# platform_designer_hps_system_hps_0_hps register map
Vendor: default_vendor.com; File version: 0.0
Registers are 32-bit, read-write, reset 0x0 unless marked. A register's access mark holds for its fields unless they carry their own. Offsets are from the block's base; [hi:lo] are bit positions; {n}, {i} and the like mark numbered series.

## sysmgr (part 2 of 3) — Registers in the System Manager module
Base 0xFFD08000
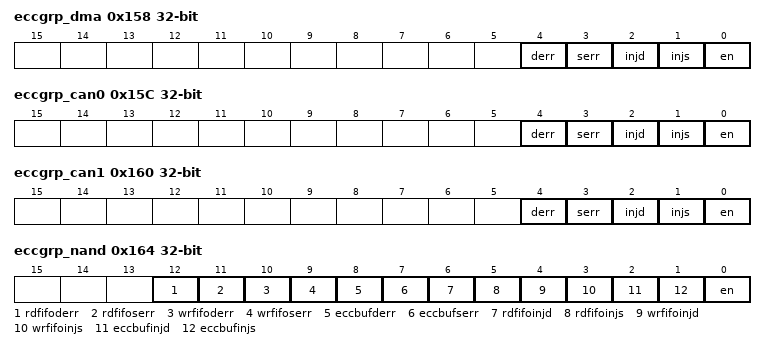
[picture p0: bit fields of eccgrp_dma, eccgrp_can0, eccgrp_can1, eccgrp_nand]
0x158 eccgrp_dma — This register is used to enable ECC on the DMA RAM. ECC errors can be injected into the write path using bits in this register. This register contains interrupt status of the ECC single/double bit error. Only reset by a cold reset (ignores warm reset).
  [4] derr write-1-clears — This bit is an interrupt status bit for DMA RAM ECC double bit, non-correctable error. It is set by hardware when double bit, non-correctable error occurs in DMA RAM. Software needs to write 1 into this bit to clear the interrupt status.
  [3] serr write-1-clears — This bit is an interrupt status bit for DMA RAM ECC single, correctable error. It is set by hardware when single, correctable error occurs in DMA RAM. Software needs to write 1 into this bit to clear the interrupt status.
  [2] injd — Changing this bit from zero to one injects a double, non-correctable error into the DMA RAM. This only injects one double bit error into the DMA RAM.
  [1] injs — Changing this bit from zero to one injects a single, correctable error into the DMA RAM. This only injects one error into the DMA RAM.
  [0] en — Enable ECC for DMA RAM
0x15C eccgrp_can0 — This register is used to enable ECC on the CAN0 RAM. ECC errors can be injected into the write path using bits in this register. This register contains interrupt status of the ECC single/double bit error. Only reset by a cold reset (ignores warm reset).
  [4] derr write-1-clears — This bit is an interrupt status bit for CAN0 RAM ECC double bit, non-correctable error. It is set by hardware when double bit, non-correctable error occurs in CAN0 RAM. Software needs to write 1 into this bit to clear the interrupt status.
  [3] serr write-1-clears — This bit is an interrupt status bit for CAN0 RAM ECC single, correctable error. It is set by hardware when single, correctable error occurs in CAN0 RAM. Software needs to write 1 into this bit to clear the interrupt status.
  [2] injd — Changing this bit from zero to one injects a double, non-correctable error into the CAN0 RAM. This only injects one double bit error into the CAN0 RAM.
  [1] injs — Changing this bit from zero to one injects a single, correctable error into the CAN0 RAM. This only injects one error into the CAN0 RAM.
  [0] en — Enable ECC for CAN0 RAM
0x160 eccgrp_can1 — This register is used to enable ECC on the CAN1 RAM. ECC errors can be injected into the write path using bits in this register. This register contains interrupt status of the ECC single/double bit error. Only reset by a cold reset (ignores warm reset).
  [4] derr write-1-clears — This bit is an interrupt status bit for CAN1 RAM ECC double bit, non-correctable error. It is set by hardware when double bit, non-correctable error occurs in CAN1 RAM. Software needs to write 1 into this bit to clear the interrupt status.
  [3] serr write-1-clears — This bit is an interrupt status bit for CAN1 RAM ECC single, correctable error. It is set by hardware when single, correctable error occurs in CAN1 RAM. Software needs to write 1 into this bit to clear the interrupt status.
  [2] injd — Changing this bit from zero to one injects a double, non-correctable error into the CAN1 RAM. This only injects one double bit error into the CAN1 RAM.
  [1] injs — Changing this bit from zero to one injects a single, correctable error into the CAN1 RAM. This only injects one error into the CAN1 RAM.
  [0] en — Enable ECC for CAN1 RAM
0x164 eccgrp_nand — This register is used to enable ECC on the NAND RAM. ECC errors can be injected into the write path using bits in this register. This register contains interrupt status of the ECC single/double bit error. Only reset by a cold reset (ignores warm reset).
  [12] rdfifoderr write-1-clears — This bit is an interrupt status bit for NAND RDFIFO RAM ECC double bit, non-correctable error. It is set by hardware when double bit, non-correctable error occurs in NAND RDFIFO RAM. Software needs to write 1 into this bit to clear the interrupt status.
  [11] rdfifoserr write-1-clears — This bit is an interrupt status bit for NAND RDFIFO RAM ECC single, correctable error. It is set by hardware when single, correctable error occurs in NAND RDFIFO RAM. Software needs to write 1 into this bit to clear the interrupt status.
  [10] wrfifoderr write-1-clears — This bit is an interrupt status bit for NAND WRFIFO RAM ECC double bit, non-correctable error. It is set by hardware when double bit, non-correctable error occurs in NAND WRFIFO RAM. Software needs to write 1 into this bit to clear the interrupt status.
  [9] wrfifoserr write-1-clears — This bit is an interrupt status bit for NAND WRFIFO RAM ECC single, correctable error. It is set by hardware when single, correctable error occurs in NAND WRFIFO RAM. Software needs to write 1 into this bit to clear the interrupt status.
  [8] eccbufderr write-1-clears — This bit is an interrupt status bit for NAND ECCBUFFER RAM ECC double bit, non-correctable error. It is set by hardware when double bit, non-correctable error occurs in NAND ECCBUFFER RAM. Software needs to write 1 into this bit to clear the interrupt status.
  [7] eccbufserr write-1-clears — This bit is an interrupt status bit for NAND ECCBUFFER RAM ECC single, correctable error. It is set by hardware when single, correctable error occurs in NAND ECCBUFFER RAM. Software needs to write 1 into this bit to clear the interrupt status.
  [6] rdfifoinjd — Changing this bit from zero to one injects a double, non-correctable error into the NAND RDFIFO RAM. This only injects one double bit error into the NAND RDFIFO RAM.
  [5] rdfifoinjs — Changing this bit from zero to one injects a single, correctable error into the NAND RDFIFO RAM. This only injects one error into the NAND RDFIFO RAM.
  [4] wrfifoinjd — Changing this bit from zero to one injects a double, non-correctable error into the NAND WRFIFO RAM. This only injects one double bit error into the NAND WRFIFO RAM.
  [3] wrfifoinjs — Changing this bit from zero to one injects a single, correctable error into the NAND WRFIFO RAM. This only injects one error into the NAND WRFIFO RAM.
  [2] eccbufinjd — Changing this bit from zero to one injects a double, non-correctable error into the NAND ECCBUFFER RAM. This only injects one double bit error into the NAND ECCBUFFER RAM.
  [1] eccbufinjs — Changing this bit from zero to one injects a single, correctable error into the NAND ECCBUFFER RAM. This only injects one error into the NAND ECCBUFFER RAM.
  [0] en — Enable ECC for NAND RAM
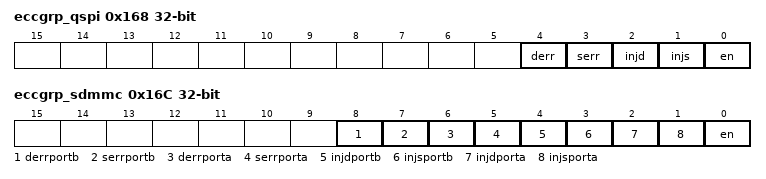
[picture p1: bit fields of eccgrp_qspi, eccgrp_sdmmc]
0x168 eccgrp_qspi — This register is used to enable ECC on the QSPI RAM. ECC errors can be injected into the write path using bits in this register. This register contains interrupt status of the ECC single/double bit error. Only reset by a cold reset (ignores warm reset).
  [4] derr write-1-clears — This bit is an interrupt status bit for QSPI RAM ECC double bit, non-correctable error. It is set by hardware when double bit, non-correctable error occurs in QSPI RAM. Software needs to write 1 into this bit to clear the interrupt status.
  [3] serr write-1-clears — This bit is an interrupt status bit for QSPI RAM ECC single, correctable error. It is set by hardware when single, correctable error occurs in QSPI RAM. Software needs to write 1 into this bit to clear the interrupt status.
  [2] injd — Changing this bit from zero to one injects a double, non-correctable error into the QSPI RAM. This only injects one double bit error into the QSPI RAM.
  [1] injs — Changing this bit from zero to one injects a single, correctable error into the QSPI RAM. This only injects one error into the QSPI RAM.
  [0] en — Enable ECC for QSPI RAM
0x16C eccgrp_sdmmc — This register is used to enable ECC on the SDMMC RAM.ECC errors can be injected into the write path using bits in this register. Only reset by a cold reset (ignores warm reset).
  [8] derrportb write-1-clears — This bit is an interrupt status bit for SDMMC Port B RAM ECC double bit, non-correctable error. It is set by hardware when double bit, non-correctable error occurs in SDMMC Port B RAM. Software needs to write 1 into this bit to clear the interrupt status.
  [7] serrportb write-1-clears — This bit is an interrupt status bit for SDMMC Port B RAM ECC single, correctable error. It is set by hardware when single, correctable error occurs in SDMMC Port B RAM. Software needs to write 1 into this bit to clear the interrupt status.
  [6] derrporta write-1-clears — This bit is an interrupt status bit for SDMMC Port A RAM ECC double bit, non-correctable error. It is set by hardware when double bit, non-correctable error occurs in SDMMC Port A RAM. Software needs to write 1 into this bit to clear the interrupt status.
  [5] serrporta write-1-clears — This bit is an interrupt status bit for SDMMC Port A RAM ECC single, correctable error. It is set by hardware when single, correctable error occurs in SDMMC Port A RAM. Software needs to write 1 into this bit to clear the interrupt status.
  [4] injdportb — Changing this bit from zero to one injects a double, non-correctable error into the SDMMC RAM at Port B. This only injects one double bit error into the SDMMC RAM at Port B.
  [3] injsportb — Changing this bit from zero to one injects a single, correctable error into the SDMMC RAM at Port B. This only injects one error into the SDMMC RAM at Port B.
  [2] injdporta — Changing this bit from zero to one injects a double, non-correctable error into the SDMMC RAM at Port A. This only injects one double bit error into the SDMMC RAM at Port A.
  [1] injsporta — Changing this bit from zero to one injects a single, correctable error into the SDMMC RAM at Port A. This only injects one error into the SDMMC RAM at Port A.
  [0] en — Enable ECC for SDMMC RAM
0x400 pinmuxgrp_EMACIO0 — This register is used to control the peripherals connected to emac0_tx_clk Only reset by a cold reset (ignores warm reset). NOTE: These registers should not be modified after IO configuration.There is no support for dynamically changing the Pin Mux selections.
  [1:0] sel — Select peripheral signals connected emac0_tx_clk. 0 : Pin is connected to GPIO/LoanIO number 0. 1 : Pin is connected to Peripheral signal not applicable. 2 : Pin is connected to Peripheral signal not applicable. 3 : Pin is connected to Peripheral signal RGMII0.TX_CLK.
{0x400+4i} pinmuxgrp_EMACIO{i} (i=1..4) — This register is used to control the peripherals connected to emac0_tx_d{i-1} Only reset by a cold reset (ignores warm reset). NOTE: These registers should not be modified after IO configuration.There is no support for dynamically changing the Pin Mux selections.
  [1:0] sel — Select peripheral signals connected emac0_tx_d{i-1}. 0 : Pin is connected to GPIO/LoanIO number {i}. 1 : Pin is connected to Peripheral signal not applicable. 2 : Pin is connected to Peripheral signal USB1.D{i-1}. 3 : Pin is connected to Peripheral signal RGMII0.TXD{i-1}.
0x414 pinmuxgrp_EMACIO5 — This register is used to control the peripherals connected to emac0_rx_d0 Only reset by a cold reset (ignores warm reset). NOTE: These registers should not be modified after IO configuration.There is no support for dynamically changing the Pin Mux selections.
  [1:0] sel — Select peripheral signals connected emac0_rx_d0. 0 : Pin is connected to GPIO/LoanIO number 5. 1 : Pin is connected to Peripheral signal not applicable. 2 : Pin is connected to Peripheral signal USB1.D4. 3 : Pin is connected to Peripheral signal RGMII0.RXD0.
0x418 pinmuxgrp_EMACIO6 — This register is used to control the peripherals connected to emac0_mdio Only reset by a cold reset (ignores warm reset). NOTE: These registers should not be modified after IO configuration.There is no support for dynamically changing the Pin Mux selections.
  [1:0] sel — Select peripheral signals connected emac0_mdio. 0 : Pin is connected to GPIO/LoanIO number 6. 1 : Pin is connected to Peripheral signal I2C2.SDA. 2 : Pin is connected to Peripheral signal USB1.D5. 3 : Pin is connected to Peripheral signal RGMII0.MDIO.
0x41C pinmuxgrp_EMACIO7 — This register is used to control the peripherals connected to emac0_mdc Only reset by a cold reset (ignores warm reset). NOTE: These registers should not be modified after IO configuration.There is no support for dynamically changing the Pin Mux selections.
  [1:0] sel — Select peripheral signals connected emac0_mdc. 0 : Pin is connected to GPIO/LoanIO number 7. 1 : Pin is connected to Peripheral signal I2C2.SCL. 2 : Pin is connected to Peripheral signal USB1.D6. 3 : Pin is connected to Peripheral signal RGMII0.MDC.
0x420 pinmuxgrp_EMACIO8 — This register is used to control the peripherals connected to emac0_rx_ctl Only reset by a cold reset (ignores warm reset). NOTE: These registers should not be modified after IO configuration.There is no support for dynamically changing the Pin Mux selections.
  [1:0] sel — Select peripheral signals connected emac0_rx_ctl. 0 : Pin is connected to GPIO/LoanIO number 8. 1 : Pin is connected to Peripheral signal not applicable. 2 : Pin is connected to Peripheral signal USB1.D7. 3 : Pin is connected to Peripheral signal RGMII0.RX_CTL.
0x424 pinmuxgrp_EMACIO9 — This register is used to control the peripherals connected to emac0_tx_ctl Only reset by a cold reset (ignores warm reset). NOTE: These registers should not be modified after IO configuration.There is no support for dynamically changing the Pin Mux selections.
  [1:0] sel — Select peripheral signals connected emac0_tx_ctl. 0 : Pin is connected to GPIO/LoanIO number 9. 1 : Pin is connected to Peripheral signal not applicable. 2 : Pin is connected to Peripheral signal not applicable. 3 : Pin is connected to Peripheral signal RGMII0.TX_CTL.
0x428 pinmuxgrp_EMACIO10 — This register is used to control the peripherals connected to emac0_rx_clk Only reset by a cold reset (ignores warm reset). NOTE: These registers should not be modified after IO configuration.There is no support for dynamically changing the Pin Mux selections.
  [1:0] sel — Select peripheral signals connected emac0_rx_clk. 0 : Pin is connected to GPIO/LoanIO number 10. 1 : Pin is connected to Peripheral signal not applicable. 2 : Pin is connected to Peripheral signal USB1.CLK. 3 : Pin is connected to Peripheral signal RGMII0.RX_CLK.
0x42C pinmuxgrp_EMACIO11 — This register is used to control the peripherals connected to emac0_rx_d1 Only reset by a cold reset (ignores warm reset). NOTE: These registers should not be modified after IO configuration.There is no support for dynamically changing the Pin Mux selections.
  [1:0] sel — Select peripheral signals connected emac0_rx_d1. 0 : Pin is connected to GPIO/LoanIO number 11. 1 : Pin is connected to Peripheral signal not applicable. 2 : Pin is connected to Peripheral signal USB1.STP. 3 : Pin is connected to Peripheral signal RGMII0.RXD1.
0x430 pinmuxgrp_EMACIO12 — This register is used to control the peripherals connected to emac0_rx_d2 Only reset by a cold reset (ignores warm reset). NOTE: These registers should not be modified after IO configuration.There is no support for dynamically changing the Pin Mux selections.
  [1:0] sel — Select peripheral signals connected emac0_rx_d2. 0 : Pin is connected to GPIO/LoanIO number 12. 1 : Pin is connected to Peripheral signal not applicable. 2 : Pin is connected to Peripheral signal USB1.DIR. 3 : Pin is connected to Peripheral signal RGMII0.RXD2.
0x434 pinmuxgrp_EMACIO13 — This register is used to control the peripherals connected to emac0_rx_d3 Only reset by a cold reset (ignores warm reset). NOTE: These registers should not be modified after IO configuration.There is no support for dynamically changing the Pin Mux selections.
  [1:0] sel — Select peripheral signals connected emac0_rx_d3. 0 : Pin is connected to GPIO/LoanIO number 13. 1 : Pin is connected to Peripheral signal not applicable. 2 : Pin is connected to Peripheral signal USB1.NXT. 3 : Pin is connected to Peripheral signal RGMII0.RXD3.
0x438 pinmuxgrp_EMACIO14 — This register is used to control the peripherals connected to emac1_tx_clk Only reset by a cold reset (ignores warm reset). NOTE: These registers should not be modified after IO configuration.There is no support for dynamically changing the Pin Mux selections.
  [1:0] sel — Select peripheral signals connected emac1_tx_clk. 0 : Pin is connected to GPIO/LoanIO number 48. 1 : Pin is connected to Peripheral signal not applicable. 2 : Pin is connected to Peripheral signal not applicable. 3 : Pin is connected to Peripheral signal RGMII1.TX_CLK.
0x43C pinmuxgrp_EMACIO15 — This register is used to control the peripherals connected to emac1_tx_d0 Only reset by a cold reset (ignores warm reset). NOTE: These registers should not be modified after IO configuration.There is no support for dynamically changing the Pin Mux selections.
  [1:0] sel — Select peripheral signals connected emac1_tx_d0. 0 : Pin is connected to GPIO/LoanIO number 49. 1 : Pin is connected to Peripheral signal not applicable. 2 : Pin is connected to Peripheral signal not applicable. 3 : Pin is connected to Peripheral signal RGMII1.TXD0.
0x440 pinmuxgrp_EMACIO16 — This register is used to control the peripherals connected to emac1_tx_d1 Only reset by a cold reset (ignores warm reset). NOTE: These registers should not be modified after IO configuration.There is no support for dynamically changing the Pin Mux selections.
  [1:0] sel — Select peripheral signals connected emac1_tx_d1. 0 : Pin is connected to GPIO/LoanIO number 50. 1 : Pin is connected to Peripheral signal not applicable. 2 : Pin is connected to Peripheral signal not applicable. 3 : Pin is connected to Peripheral signal RGMII1.TXD1.
0x444 pinmuxgrp_EMACIO17 — This register is used to control the peripherals connected to emac1_tx_ctl Only reset by a cold reset (ignores warm reset). NOTE: These registers should not be modified after IO configuration.There is no support for dynamically changing the Pin Mux selections.
  [1:0] sel — Select peripheral signals connected emac1_tx_ctl. 0 : Pin is connected to GPIO/LoanIO number 51. 1 : Pin is connected to Peripheral signal not applicable. 2 : Pin is connected to Peripheral signal not applicable. 3 : Pin is connected to Peripheral signal RGMII1.TX_CTL.
0x448 pinmuxgrp_EMACIO18 — This register is used to control the peripherals connected to emac1_rx_d0 Only reset by a cold reset (ignores warm reset). NOTE: These registers should not be modified after IO configuration.There is no support for dynamically changing the Pin Mux selections.
  [1:0] sel — Select peripheral signals connected emac1_rx_d0. 0 : Pin is connected to GPIO/LoanIO number 52. 1 : Pin is connected to Peripheral signal not applicable. 2 : Pin is connected to Peripheral signal not applicable. 3 : Pin is connected to Peripheral signal RGMII1.RXD0.
0x44C pinmuxgrp_EMACIO19 — This register is used to control the peripherals connected to emac1_rx_d1 Only reset by a cold reset (ignores warm reset). NOTE: These registers should not be modified after IO configuration.There is no support for dynamically changing the Pin Mux selections.
  [1:0] sel — Select peripheral signals connected emac1_rx_d1. 0 : Pin is connected to GPIO/LoanIO number 53. 1 : Pin is connected to Peripheral signal not applicable. 2 : Pin is connected to Peripheral signal not applicable. 3 : Pin is connected to Peripheral signal RGMII1.RXD1.
0x450 pinmuxgrp_FLASHIO0 — This register is used to control the peripherals connected to sdmmc_cmd Only reset by a cold reset (ignores warm reset). NOTE: These registers should not be modified after IO configuration.There is no support for dynamically changing the Pin Mux selections.
  [1:0] sel — Select peripheral signals connected sdmmc_cmd. 0 : Pin is connected to GPIO/LoanIO number 36. 1 : Pin is connected to Peripheral signal not applicable. 2 : Pin is connected to Peripheral signal USB0.D0. 3 : Pin is connected to Peripheral signal SDMMC.CMD.
0x454 pinmuxgrp_FLASHIO1 — This register is used to control the peripherals connected to sdmmc_pwren Only reset by a cold reset (ignores warm reset). NOTE: These registers should not be modified after IO configuration.There is no support for dynamically changing the Pin Mux selections.
  [1:0] sel — Select peripheral signals connected sdmmc_pwren. 0 : Pin is connected to GPIO/LoanIO number 37. 1 : Pin is connected to Peripheral signal not applicable. 2 : Pin is connected to Peripheral signal USB0.D1. 3 : Pin is connected to Peripheral signal SDMMC.PWREN.
0x458 pinmuxgrp_FLASHIO2 — This register is used to control the peripherals connected to sdmmc_d0 Only reset by a cold reset (ignores warm reset). NOTE: These registers should not be modified after IO configuration.There is no support for dynamically changing the Pin Mux selections.
  [1:0] sel — Select peripheral signals connected sdmmc_d0. 0 : Pin is connected to GPIO/LoanIO number 38. 1 : Pin is connected to Peripheral signal not applicable. 2 : Pin is connected to Peripheral signal USB0.D2. 3 : Pin is connected to Peripheral signal SDMMC.D0.
0x45C pinmuxgrp_FLASHIO3 — This register is used to control the peripherals connected to sdmmc_d1 Only reset by a cold reset (ignores warm reset). NOTE: These registers should not be modified after IO configuration.There is no support for dynamically changing the Pin Mux selections.
  [1:0] sel — Select peripheral signals connected sdmmc_d1. 0 : Pin is connected to GPIO/LoanIO number 39. 1 : Pin is connected to Peripheral signal not applicable. 2 : Pin is connected to Peripheral signal USB0.D3. 3 : Pin is connected to Peripheral signal SDMMC.D1.
{0x450+4i} pinmuxgrp_FLASHIO{i} (i=4..7) — This register is used to control the peripherals connected to sdmmc_d{i} Only reset by a cold reset (ignores warm reset). NOTE: These registers should not be modified after IO configuration.There is no support for dynamically changing the Pin Mux selections.
  [1:0] sel — Select peripheral signals connected sdmmc_d{i}. 0 : Pin is connected to GPIO/LoanIO number {i+36}. 1 : Pin is connected to Peripheral signal not applicable. 2 : Pin is connected to Peripheral signal USB0.D{i}. 3 : Pin is connected to Peripheral signal SDMMC.D{i}.
0x470 pinmuxgrp_FLASHIO8 — This register is used to control the peripherals connected to sdmmc_clk_in Only reset by a cold reset (ignores warm reset). NOTE: These registers should not be modified after IO configuration.There is no support for dynamically changing the Pin Mux selections.
  [1:0] sel — Select peripheral signals connected sdmmc_clk_in. 0 : Pin is connected to GPIO/LoanIO number 44. 1 : Pin is connected to Peripheral signal not applicable. 2 : Pin is connected to Peripheral signal USB0.CLK. 3 : Pin is connected to Peripheral signal SDMMC.CLK_IN.
0x474 pinmuxgrp_FLASHIO9 — This register is used to control the peripherals connected to sdmmc_clk Only reset by a cold reset (ignores warm reset). NOTE: These registers should not be modified after IO configuration.There is no support for dynamically changing the Pin Mux selections.
  [1:0] sel — Select peripheral signals connected sdmmc_clk. 0 : Pin is connected to GPIO/LoanIO number 45. 1 : Pin is connected to Peripheral signal not applicable. 2 : Pin is connected to Peripheral signal USB0.STP. 3 : Pin is connected to Peripheral signal SDMMC.CLK.
0x478 pinmuxgrp_FLASHIO10 — This register is used to control the peripherals connected to sdmmc_d2 Only reset by a cold reset (ignores warm reset). NOTE: These registers should not be modified after IO configuration.There is no support for dynamically changing the Pin Mux selections.
  [1:0] sel — Select peripheral signals connected sdmmc_d2. 0 : Pin is connected to GPIO/LoanIO number 46. 1 : Pin is connected to Peripheral signal not applicable. 2 : Pin is connected to Peripheral signal USB0.DIR. 3 : Pin is connected to Peripheral signal SDMMC.D2.
0x47C pinmuxgrp_FLASHIO11 — This register is used to control the peripherals connected to sdmmc_d3 Only reset by a cold reset (ignores warm reset). NOTE: These registers should not be modified after IO configuration.There is no support for dynamically changing the Pin Mux selections.
  [1:0] sel — Select peripheral signals connected sdmmc_d3. 0 : Pin is connected to GPIO/LoanIO number 47. 1 : Pin is connected to Peripheral signal not applicable. 2 : Pin is connected to Peripheral signal USB0.NXT. 3 : Pin is connected to Peripheral signal SDMMC.D3.
0x480 pinmuxgrp_GENERALIO0 — This register is used to control the peripherals connected to trace_clk Only reset by a cold reset (ignores warm reset). NOTE: These registers should not be modified after IO configuration.There is no support for dynamically changing the Pin Mux selections.
  [1:0] sel — Select peripheral signals connected trace_clk. 0 : Pin is connected to GPIO/LoanIO number 48. 1 : Pin is connected to Peripheral signal not applicable. 2 : Pin is connected to Peripheral signal not applicable. 3 : Pin is connected to Peripheral signal TRACE.CLK.
0x484 pinmuxgrp_GENERALIO1 — This register is used to control the peripherals connected to trace_d0 Only reset by a cold reset (ignores warm reset). NOTE: These registers should not be modified after IO configuration.There is no support for dynamically changing the Pin Mux selections.
  [1:0] sel — Select peripheral signals connected trace_d0. 0 : Pin is connected to GPIO/LoanIO number 49. 1 : Pin is connected to Peripheral signal UART0.RX. 2 : Pin is connected to Peripheral signal SPIS0.CLK. 3 : Pin is connected to Peripheral signal TRACE.D0.
0x488 pinmuxgrp_GENERALIO2 — This register is used to control the peripherals connected to trace_d1 Only reset by a cold reset (ignores warm reset). NOTE: These registers should not be modified after IO configuration.There is no support for dynamically changing the Pin Mux selections.
  [1:0] sel — Select peripheral signals connected trace_d1. 0 : Pin is connected to GPIO/LoanIO number 50. 1 : Pin is connected to Peripheral signal UART0.TX. 2 : Pin is connected to Peripheral signal SPIS0.MOSI. 3 : Pin is connected to Peripheral signal TRACE.D1.
0x48C pinmuxgrp_GENERALIO3 — This register is used to control the peripherals connected to trace_d2 Only reset by a cold reset (ignores warm reset). NOTE: These registers should not be modified after IO configuration.There is no support for dynamically changing the Pin Mux selections.
  [1:0] sel — Select peripheral signals connected trace_d2. 0 : Pin is connected to GPIO/LoanIO number 51. 1 : Pin is connected to Peripheral signal I2C1.SDA. 2 : Pin is connected to Peripheral signal SPIS0.MISO. 3 : Pin is connected to Peripheral signal TRACE.D2.
0x490 pinmuxgrp_GENERALIO4 — This register is used to control the peripherals connected to trace_d3 Only reset by a cold reset (ignores warm reset). NOTE: These registers should not be modified after IO configuration.There is no support for dynamically changing the Pin Mux selections.
  [1:0] sel — Select peripheral signals connected trace_d3. 0 : Pin is connected to GPIO/LoanIO number 52. 1 : Pin is connected to Peripheral signal I2C1.SCL. 2 : Pin is connected to Peripheral signal SPIS0.SS0. 3 : Pin is connected to Peripheral signal TRACE.D3.
0x494 pinmuxgrp_GENERALIO5 — This register is used to control the peripherals connected to trace_d4 Only reset by a cold reset (ignores warm reset). NOTE: These registers should not be modified after IO configuration.There is no support for dynamically changing the Pin Mux selections.
  [1:0] sel — Select peripheral signals connected trace_d4. 0 : Pin is connected to GPIO/LoanIO number 53. 1 : Pin is connected to Peripheral signal CAN1.RX. 2 : Pin is connected to Peripheral signal SPIS1.CLK. 3 : Pin is connected to Peripheral signal TRACE.D4.
0x498 pinmuxgrp_GENERALIO6 — This register is used to control the peripherals connected to trace_d5 Only reset by a cold reset (ignores warm reset). NOTE: These registers should not be modified after IO configuration.There is no support for dynamically changing the Pin Mux selections.
  [1:0] sel — Select peripheral signals connected trace_d5. 0 : Pin is connected to GPIO/LoanIO number 54. 1 : Pin is connected to Peripheral signal CAN1.TX. 2 : Pin is connected to Peripheral signal SPIS1.MOSI. 3 : Pin is connected to Peripheral signal TRACE.D5.
0x49C pinmuxgrp_GENERALIO7 — This register is used to control the peripherals connected to trace_d6 Only reset by a cold reset (ignores warm reset). NOTE: These registers should not be modified after IO configuration.There is no support for dynamically changing the Pin Mux selections.
  [1:0] sel — Select peripheral signals connected trace_d6. 0 : Pin is connected to GPIO/LoanIO number 55. 1 : Pin is connected to Peripheral signal I2C0.SDA. 2 : Pin is connected to Peripheral signal SPIS1.SS0. 3 : Pin is connected to Peripheral signal TRACE.D6.
0x4A0 pinmuxgrp_GENERALIO8 — This register is used to control the peripherals connected to trace_d7 Only reset by a cold reset (ignores warm reset). NOTE: These registers should not be modified after IO configuration.There is no support for dynamically changing the Pin Mux selections.
  [1:0] sel — Select peripheral signals connected trace_d7. 0 : Pin is connected to GPIO/LoanIO number 56. 1 : Pin is connected to Peripheral signal I2C0.SCL. 2 : Pin is connected to Peripheral signal SPIS1.MISO. 3 : Pin is connected to Peripheral signal TRACE.D7.
0x4A4 pinmuxgrp_GENERALIO9 — This register is used to control the peripherals connected to spim0_clk Only reset by a cold reset (ignores warm reset). NOTE: These registers should not be modified after IO configuration.There is no support for dynamically changing the Pin Mux selections.
  [1:0] sel — Select peripheral signals connected spim0_clk. 0 : Pin is connected to GPIO/LoanIO number 57. 1 : Pin is connected to Peripheral signal UART0.CTS. 2 : Pin is connected to Peripheral signal I2C1.SDA. 3 : Pin is connected to Peripheral signal SPIM0.CLK.
0x4A8 pinmuxgrp_GENERALIO10 — This register is used to control the peripherals connected to spim0_mosi Only reset by a cold reset (ignores warm reset). NOTE: These registers should not be modified after IO configuration.There is no support for dynamically changing the Pin Mux selections.
  [1:0] sel — Select peripheral signals connected spim0_mosi. 0 : Pin is connected to GPIO/LoanIO number 58. 1 : Pin is connected to Peripheral signal UART0.RTS. 2 : Pin is connected to Peripheral signal I2C1.SCL. 3 : Pin is connected to Peripheral signal SPIM0.MOSI.
0x4AC pinmuxgrp_GENERALIO11 — This register is used to control the peripherals connected to spim0_miso Only reset by a cold reset (ignores warm reset). NOTE: These registers should not be modified after IO configuration.There is no support for dynamically changing the Pin Mux selections.
  [1:0] sel — Select peripheral signals connected spim0_miso. 0 : Pin is connected to GPIO/LoanIO number 59. 1 : Pin is connected to Peripheral signal UART1.CTS. 2 : Pin is connected to Peripheral signal CAN1.RX. 3 : Pin is connected to Peripheral signal SPIM0.MISO.
0x4B0 pinmuxgrp_GENERALIO12 — This register is used to control the peripherals connected to spim0_ss0 Only reset by a cold reset (ignores warm reset). NOTE: These registers should not be modified after IO configuration.There is no support for dynamically changing the Pin Mux selections.
  [1:0] sel — Select peripheral signals connected spim0_ss0. 0 : Pin is connected to GPIO/LoanIO number 60. 1 : Pin is connected to Peripheral signal UART1.RTS. 2 : Pin is connected to Peripheral signal CAN1.TX. 3 : Pin is connected to Peripheral signal SPIM0.SS0.
0x4B4 pinmuxgrp_GENERALIO13 — This register is used to control the peripherals connected to uart0_rx Only reset by a cold reset (ignores warm reset). NOTE: These registers should not be modified after IO configuration.There is no support for dynamically changing the Pin Mux selections.
  [1:0] sel — Select peripheral signals connected uart0_rx. 0 : Pin is connected to GPIO/LoanIO number 61. 1 : Pin is connected to Peripheral signal SPIM0.SS1. 2 : Pin is connected to Peripheral signal CAN0.RX. 3 : Pin is connected to Peripheral signal UART0.RX.
